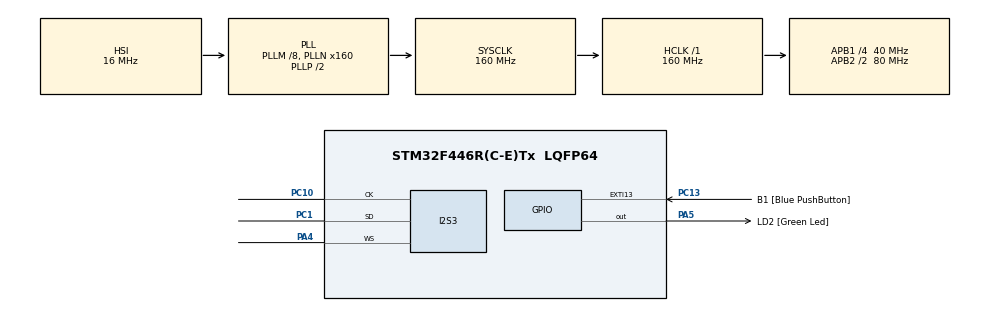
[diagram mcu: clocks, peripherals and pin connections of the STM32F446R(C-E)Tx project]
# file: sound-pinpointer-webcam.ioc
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Dma.Request0=SPI3_RX
Dma.SPI3_RX.0.Direction=DMA_PERIPH_TO_MEMORY
Dma.SPI3_RX.0.FIFOMode=DMA_FIFOMODE_DISABLE
Dma.SPI3_RX.0.Instance=DMA1_Stream0
Dma.SPI3_RX.0.MemDataAlignment=DMA_MDATAALIGN_HALFWORD
Dma.SPI3_RX.0.MemInc=DMA_MINC_ENABLE
Dma.SPI3_RX.0.Mode=DMA_CIRCULAR
Dma.SPI3_RX.0.PeriphDataAlignment=DMA_PDATAALIGN_HALFWORD
Dma.SPI3_RX.0.PeriphInc=DMA_PINC_DISABLE
Dma.SPI3_RX.0.Priority=DMA_PRIORITY_LOW
I2S3.AudioFreq=I2S_AUDIOFREQ_32K
I2S3.DataFormat=I2S_DATAFORMAT_16B_EXTENDED
I2S3.ErrorAudioFreq=1.72 %
I2S3.FullDuplexMode=I2S_FULLDUPLEXMODE_DISABLE
I2S3.Instance=SPI$Index
I2S3.Mode=I2S_MODE_MASTER_RX
I2S3.RealAudioFreq=32.552 KHz
I2S3.VirtualMode=I2S_MODE_MASTER
Mcu.Family=STM32F4
Mcu.Name=STM32F446R(C-E)Tx
Mcu.Package=LQFP64
NVIC.DMA1_Stream0_IRQn=true\:0\:0\:false\:false\:true\:false\:true\:true
NVIC.PriorityGroup=NVIC_PRIORITYGROUP_0
NVIC.SPI3_IRQn=true\:0\:0\:false\:false\:true\:true\:true\:true
PA13.GPIO_Label=TMS
PA13.Signal=SYS_JTMS-SWDIO
PA14.GPIO_Label=TCK
PA14.Signal=SYS_JTCK-SWCLK
PA2.GPIO_Label=USART_TX
PA2.Signal=USART2_TX
PA3.GPIO_Label=USART_RX
PA3.Signal=USART2_RX
PA4.Mode=Half_Duplex_Master
PA4.Signal=I2S3_WS
PA5.GPIO_Label=LD2 [Green Led]
PA5.Signal=GPIO_Output
PB3.GPIO_Label=SWO
PB3.Signal=SYS_JTDO-SWO
PC1.Mode=Half_Duplex_Master
PC1.Signal=I2S3_SD
PC10.Mode=Half_Duplex_Master
PC10.Signal=I2S3_CK
PC13.GPIO_Label=B1 [Blue PushButton]
PC13.GPIO_ModeDefaultEXTI=GPIO_MODE_IT_FALLING
PC13.Signal=GPXTI13
PC14-OSC32_IN.Signal=RCC_OSC32_IN
PC15-OSC32_OUT.Signal=RCC_OSC32_OUT
PH0-OSC_IN.Signal=RCC_OSC_IN
PH1-OSC_OUT.Signal=RCC_OSC_OUT
ProjectManager.HeapSize=0x200
ProjectManager.StackSize=0x400
ProjectManager.TargetToolchain=STM32CubeIDE
RCC.AHBFreq_Value=160000000
RCC.APB1CLKDivider=RCC_HCLK_DIV4
RCC.APB1Freq_Value=40000000
RCC.APB1TimFreq_Value=80000000
RCC.APB2CLKDivider=RCC_HCLK_DIV2
RCC.APB2Freq_Value=80000000
RCC.APB2TimFreq_Value=160000000
RCC.CortexFreq_Value=160000000
RCC.FLatency-AdvancedSettings=FLASH_LATENCY_5
RCC.HCLKFreq_Value=160000000
RCC.HSE_VALUE=8000000
RCC.HSI_VALUE=16000000
RCC.LSE_VALUE=32768
RCC.PLLI2SM=8
RCC.PLLI2SN=50
RCC.PLLM=8
RCC.PLLN=160
RCC.SYSCLKFreq_VALUE=160000000
RCC.SYSCLKSource=RCC_SYSCLKSOURCE_PLLCLK
RCC.USBFreq_Value=160000000
RCC.VCOOutputFreq_Value=320000000
board=NUCLEO-F446RE

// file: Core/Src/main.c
/* USER CODE BEGIN Header */
/**
 ******************************************************************************
 * @file           : main.c
 * @brief          : Main program body
 ******************************************************************************
 * @attention
 *
 * Copyright (c) 2025 STMicroelectronics.
 * All rights reserved.
 *
 * This software is licensed under terms that can be found in the LICENSE file
 * in the root directory of this software component.
 * If no LICENSE file comes with this software, it is provided AS-IS.
 *
 ******************************************************************************
 */
/* USER CODE END Header */
#include "main.h"

/* USER CODE BEGIN Includes */

#include "microphone.h"

/* USER CODE END Includes */

I2S_HandleTypeDef hi2s3;
DMA_HandleTypeDef hdma_spi3_rx;

/* USER CODE BEGIN PV */

volatile static microphone_t MICROPHONE_1[MICROPHONE_BUFFER_LENGTH];

// Moving average of Microphone 1 values
static microphone_t MICROPHONE_1_AVERAGE;

/* USER CODE END PV */

void SystemClock_Config(void);
static void MX_GPIO_Init(void);
static void MX_DMA_Init(void);
static void MX_I2S3_Init(void);

/* USER CODE BEGIN 0 */

void HAL_I2S_RxCpltCallback(I2S_HandleTypeDef *hi2s){
	MICROPHONE_1_AVERAGE =  normalize(average(MICROPHONE_1, MICROPHONE_BUFFER_LENGTH));
}

/* USER CODE END 0 */

int main(void)
{

  /* MCU Configuration--------------------------------------------------------*/

  /* Reset of all peripherals, Initializes the Flash interface and the Systick. */
  HAL_Init();

  /* Configure the system clock */
  SystemClock_Config();

  /* Initialize all configured peripherals */
  MX_GPIO_Init();
  MX_DMA_Init();
  MX_I2S3_Init();
  /* USER CODE BEGIN 2 */

	HAL_I2S_Receive_DMA(&hi2s3, (uint16_t*)MICROPHONE_1,
			sizeof(MICROPHONE_1) / 2);

  /* USER CODE END 2 */

  /* Infinite loop */
	while (1) {

	}
}

void SystemClock_Config(void)
{
  RCC_OscInitTypeDef RCC_OscInitStruct = {0};
  RCC_ClkInitTypeDef RCC_ClkInitStruct = {0};

  /** Configure the main internal regulator output voltage
  */
  __HAL_RCC_PWR_CLK_ENABLE();
  __HAL_PWR_VOLTAGESCALING_CONFIG(PWR_REGULATOR_VOLTAGE_SCALE1);

  /** Initializes the RCC Oscillators according to the specified parameters
  * in the RCC_OscInitTypeDef structure.
  */
  RCC_OscInitStruct.OscillatorType = RCC_OSCILLATORTYPE_HSI;
  RCC_OscInitStruct.HSIState = RCC_HSI_ON;
  RCC_OscInitStruct.HSICalibrationValue = RCC_HSICALIBRATION_DEFAULT;
  RCC_OscInitStruct.PLL.PLLState = RCC_PLL_ON;
  RCC_OscInitStruct.PLL.PLLSource = RCC_PLLSOURCE_HSI;
  RCC_OscInitStruct.PLL.PLLM = 8;
  RCC_OscInitStruct.PLL.PLLN = 160;
  RCC_OscInitStruct.PLL.PLLP = RCC_PLLP_DIV2;
  RCC_OscInitStruct.PLL.PLLQ = 2;
  RCC_OscInitStruct.PLL.PLLR = 2;
  if (HAL_RCC_OscConfig(&RCC_OscInitStruct) != HAL_OK)
  {
    Error_Handler();
  }

  /** Initializes the CPU, AHB and APB buses clocks
  */
  RCC_ClkInitStruct.ClockType = RCC_CLOCKTYPE_HCLK|RCC_CLOCKTYPE_SYSCLK
                              |RCC_CLOCKTYPE_PCLK1|RCC_CLOCKTYPE_PCLK2;
  RCC_ClkInitStruct.SYSCLKSource = RCC_SYSCLKSOURCE_PLLCLK;
  RCC_ClkInitStruct.AHBCLKDivider = RCC_SYSCLK_DIV1;
  RCC_ClkInitStruct.APB1CLKDivider = RCC_HCLK_DIV4;
  RCC_ClkInitStruct.APB2CLKDivider = RCC_HCLK_DIV2;

  if (HAL_RCC_ClockConfig(&RCC_ClkInitStruct, FLASH_LATENCY_5) != HAL_OK)
  {
    Error_Handler();
  }
}

static void MX_I2S3_Init(void)
{

  hi2s3.Instance = SPI3;
  hi2s3.Init.Mode = I2S_MODE_MASTER_RX;
  hi2s3.Init.Standard = I2S_STANDARD_PHILIPS;
  hi2s3.Init.DataFormat = I2S_DATAFORMAT_16B_EXTENDED;
  hi2s3.Init.MCLKOutput = I2S_MCLKOUTPUT_DISABLE;
  hi2s3.Init.AudioFreq = I2S_AUDIOFREQ_32K;
  hi2s3.Init.CPOL = I2S_CPOL_LOW;
  hi2s3.Init.ClockSource = I2S_CLOCK_PLL;
  hi2s3.Init.FullDuplexMode = I2S_FULLDUPLEXMODE_DISABLE;
  if (HAL_I2S_Init(&hi2s3) != HAL_OK)
  {
    Error_Handler();
  }

}

static void MX_DMA_Init(void)
{

  /* DMA controller clock enable */
  __HAL_RCC_DMA1_CLK_ENABLE();

  /* DMA interrupt init */
  /* DMA1_Stream0_IRQn interrupt configuration */
  HAL_NVIC_SetPriority(DMA1_Stream0_IRQn, 0, 0);
  HAL_NVIC_EnableIRQ(DMA1_Stream0_IRQn);

}

static void MX_GPIO_Init(void)
{
  GPIO_InitTypeDef GPIO_InitStruct = {0};

  /* GPIO Ports Clock Enable */
  __HAL_RCC_GPIOC_CLK_ENABLE();
  __HAL_RCC_GPIOH_CLK_ENABLE();
  __HAL_RCC_GPIOA_CLK_ENABLE();
  __HAL_RCC_GPIOB_CLK_ENABLE();

  /*Configure GPIO pin Output Level */
  HAL_GPIO_WritePin(LD2_GPIO_Port, LD2_Pin, GPIO_PIN_RESET);

  /*Configure GPIO pin : B1_Pin */
  GPIO_InitStruct.Pin = B1_Pin;
  GPIO_InitStruct.Mode = GPIO_MODE_IT_FALLING;
  GPIO_InitStruct.Pull = GPIO_NOPULL;
  HAL_GPIO_Init(B1_GPIO_Port, &GPIO_InitStruct);

  /*Configure GPIO pins : USART_TX_Pin USART_RX_Pin */
  GPIO_InitStruct.Pin = USART_TX_Pin|USART_RX_Pin;
  GPIO_InitStruct.Mode = GPIO_MODE_AF_PP;
  GPIO_InitStruct.Pull = GPIO_NOPULL;
  GPIO_InitStruct.Speed = GPIO_SPEED_FREQ_VERY_HIGH;
  GPIO_InitStruct.Alternate = GPIO_AF7_USART2;
  HAL_GPIO_Init(GPIOA, &GPIO_InitStruct);

  /*Configure GPIO pin : LD2_Pin */
  GPIO_InitStruct.Pin = LD2_Pin;
  GPIO_InitStruct.Mode = GPIO_MODE_OUTPUT_PP;
  GPIO_InitStruct.Pull = GPIO_NOPULL;
  GPIO_InitStruct.Speed = GPIO_SPEED_FREQ_LOW;
  HAL_GPIO_Init(LD2_GPIO_Port, &GPIO_InitStruct);

}

void Error_Handler(void)
{
	__disable_irq();
	while (1) {
	}
}
